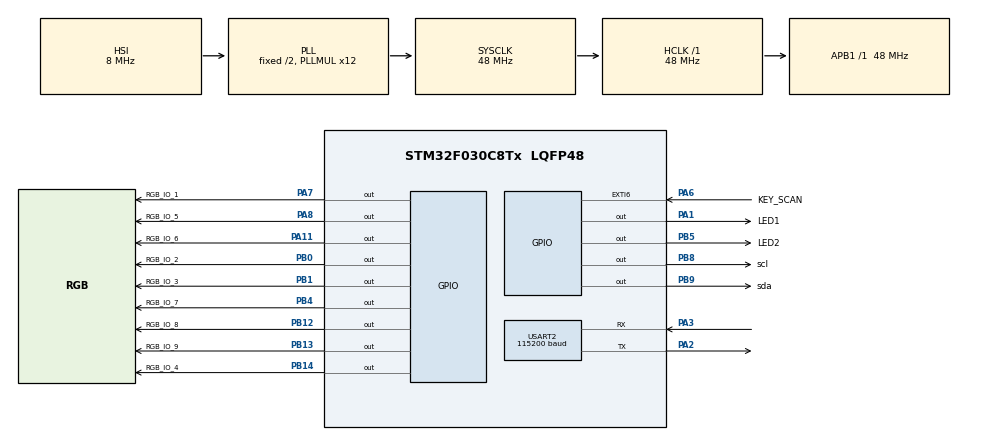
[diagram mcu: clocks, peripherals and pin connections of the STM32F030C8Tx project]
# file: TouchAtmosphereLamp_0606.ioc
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Dma.Request0=USART2_RX
Dma.Request1=USART2_TX
Dma.USART2_RX.0.Direction=DMA_PERIPH_TO_MEMORY
Dma.USART2_RX.0.Instance=DMA1_Channel5
Dma.USART2_RX.0.MemDataAlignment=DMA_MDATAALIGN_BYTE
Dma.USART2_RX.0.MemInc=DMA_MINC_ENABLE
Dma.USART2_RX.0.Mode=DMA_NORMAL
Dma.USART2_RX.0.PeriphDataAlignment=DMA_PDATAALIGN_BYTE
Dma.USART2_RX.0.PeriphInc=DMA_PINC_DISABLE
Dma.USART2_RX.0.Priority=DMA_PRIORITY_LOW
Dma.USART2_TX.1.Direction=DMA_MEMORY_TO_PERIPH
Dma.USART2_TX.1.Instance=DMA1_Channel4
Dma.USART2_TX.1.MemDataAlignment=DMA_MDATAALIGN_BYTE
Dma.USART2_TX.1.MemInc=DMA_MINC_ENABLE
Dma.USART2_TX.1.Mode=DMA_NORMAL
Dma.USART2_TX.1.PeriphDataAlignment=DMA_PDATAALIGN_BYTE
Dma.USART2_TX.1.PeriphInc=DMA_PINC_DISABLE
Dma.USART2_TX.1.Priority=DMA_PRIORITY_LOW
Mcu.Family=STM32F0
Mcu.Name=STM32F030C8Tx
Mcu.Package=LQFP48
NVIC.DMA1_Channel4_5_IRQn=true\:0\:0\:false\:false\:true\:false\:true\:true
NVIC.EXTI4_15_IRQn=true\:0\:0\:false\:false\:true\:true\:true\:true
NVIC.USART2_IRQn=true\:0\:0\:false\:false\:true\:true\:true\:true
PA1.GPIO_Label=LED1
PA1.Signal=GPIO_Output
PA11.GPIO_Label=RGB_IO_6
PA11.GPIO_PuPd=GPIO_PULLUP
PA11.Signal=GPIO_Output
PA13.Mode=Serial_Wire
PA13.Signal=SYS_SWDIO
PA14.Mode=Serial_Wire
PA14.Signal=SYS_SWCLK
PA2.GPIO_PuPd=GPIO_PULLUP
PA2.Mode=Asynchronous
PA2.Signal=USART2_TX
PA3.GPIO_PuPd=GPIO_PULLUP
PA3.Mode=Asynchronous
PA3.Signal=USART2_RX
PA6.GPIO_Label=KEY_SCAN
PA6.GPIO_ModeDefaultEXTI=GPIO_MODE_IT_FALLING
PA6.GPIO_PuPd=GPIO_PULLUP
PA6.Signal=GPXTI6
PA7.GPIO_Label=RGB_IO_1
PA7.GPIO_PuPd=GPIO_PULLUP
PA7.Signal=GPIO_Output
PA8.GPIO_Label=RGB_IO_5
PA8.GPIO_PuPd=GPIO_PULLUP
PA8.Signal=GPIO_Output
PB0.GPIO_Label=RGB_IO_2
PB0.GPIO_PuPd=GPIO_PULLUP
PB0.Signal=GPIO_Output
PB1.GPIO_Label=RGB_IO_3
PB1.GPIO_PuPd=GPIO_PULLUP
PB1.Signal=GPIO_Output
PB12.GPIO_Label=RGB_IO_8
PB12.GPIO_PuPd=GPIO_PULLUP
PB12.Signal=GPIO_Output
PB13.GPIO_Label=RGB_IO_9
PB13.GPIO_PuPd=GPIO_PULLUP
PB13.Signal=GPIO_Output
PB14.GPIO_Label=RGB_IO_4
PB14.GPIO_PuPd=GPIO_PULLUP
PB14.Signal=GPIO_Output
PB4.GPIO_Label=RGB_IO_7
PB4.GPIO_PuPd=GPIO_PULLUP
PB4.Signal=GPIO_Output
PB5.GPIO_Label=LED2
PB5.Signal=GPIO_Output
PB8.GPIO_Label=scl
PB8.Signal=GPIO_Output
PB9.GPIO_Label=sda
PB9.Signal=GPIO_Output
ProjectManager.HeapSize=0x200
ProjectManager.StackSize=0x400
ProjectManager.TargetToolchain=MDK-ARM V5.32
RCC.AHBFreq_Value=48000000
RCC.APB1Freq_Value=48000000
RCC.APB1TimFreq_Value=48000000
RCC.HCLKFreq_Value=48000000
RCC.PLLMUL=RCC_PLL_MUL12
RCC.SYSCLKFreq_VALUE=48000000
RCC.SYSCLKSource=RCC_SYSCLKSOURCE_PLLCLK
USART2.BaudRate=115200
USART2.VirtualMode-Asynchronous=VM_ASYNC
board=custom

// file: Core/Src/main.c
/* USER CODE BEGIN Header */
/**
  ******************************************************************************
  * @file           : main.c
  * @brief          : Main program body
  ******************************************************************************
  * @attention
  *
  * Copyright (c) 2022 STMicroelectronics.
  * All rights reserved.
  *
  * This software is licensed under terms that can be found in the LICENSE file
  * in the root directory of this software component.
  * If no LICENSE file comes with this software, it is provided AS-IS.
  *
  ******************************************************************************
  */
/* USER CODE END Header */
#include "main.h"

/* USER CODE BEGIN Includes */
#include "drv_serial.h"
#include "drv_rgb.h"
/* USER CODE END Includes */

 UART_HandleTypeDef huart2;
DMA_HandleTypeDef hdma_usart2_rx;
DMA_HandleTypeDef hdma_usart2_tx;

/* USER CODE BEGIN PV */
extern USART_RECEIVETYPE        UsartType2;

/* USER CODE END PV */

void SystemClock_Config(void);
static void MX_GPIO_Init(void);
static void MX_DMA_Init(void);
static void MX_USART2_UART_Init(void);

int main(void)
{

  /* MCU Configuration--------------------------------------------------------*/

  /* Reset of all peripherals, Initializes the Flash interface and the Systick. */
  HAL_Init();

  /* Configure the system clock */
  SystemClock_Config();

  /* USER CODE BEGIN SysInit */
  Drv_RGB_Init();
  /* USER CODE END SysInit */

  /* Initialize all configured peripherals */
  MX_GPIO_Init();
  MX_DMA_Init();
  MX_USART2_UART_Init();
  /* USER CODE BEGIN 2 */

  HAL_UART_Receive_DMA(&huart2, UsartType2.RX_pData, UART_RX_LEN);
  __HAL_UART_ENABLE_IT(&huart2, UART_IT_IDLE);

  Drv_SERIAL_Log("System running.");
  /* USER CODE END 2 */

  /* Infinite loop */
  /* USER CODE BEGIN WHILE */
  while (1)
  {
		Drv_LED_Proc();

    Drv_RGB_Proc();
    Drv_Panel_Proc();
    Drv_SERIAL_Proc();

    /* USER CODE END WHILE */

  }
}

void SystemClock_Config(void)
{
  RCC_OscInitTypeDef RCC_OscInitStruct = {0};
  RCC_ClkInitTypeDef RCC_ClkInitStruct = {0};

  /** Initializes the RCC Oscillators according to the specified parameters
  * in the RCC_OscInitTypeDef structure.
  */
  RCC_OscInitStruct.OscillatorType = RCC_OSCILLATORTYPE_HSI;
  RCC_OscInitStruct.HSIState = RCC_HSI_ON;
  RCC_OscInitStruct.HSICalibrationValue = RCC_HSICALIBRATION_DEFAULT;
  RCC_OscInitStruct.PLL.PLLState = RCC_PLL_ON;
  RCC_OscInitStruct.PLL.PLLSource = RCC_PLLSOURCE_HSI;
  RCC_OscInitStruct.PLL.PLLMUL = RCC_PLL_MUL12;
  RCC_OscInitStruct.PLL.PREDIV = RCC_PREDIV_DIV1;
  if (HAL_RCC_OscConfig(&RCC_OscInitStruct) != HAL_OK)
  {
    Error_Handler();
  }

  /** Initializes the CPU, AHB and APB buses clocks
  */
  RCC_ClkInitStruct.ClockType = RCC_CLOCKTYPE_HCLK|RCC_CLOCKTYPE_SYSCLK
                              |RCC_CLOCKTYPE_PCLK1;
  RCC_ClkInitStruct.SYSCLKSource = RCC_SYSCLKSOURCE_PLLCLK;
  RCC_ClkInitStruct.AHBCLKDivider = RCC_SYSCLK_DIV1;
  RCC_ClkInitStruct.APB1CLKDivider = RCC_HCLK_DIV1;

  if (HAL_RCC_ClockConfig(&RCC_ClkInitStruct, FLASH_LATENCY_1) != HAL_OK)
  {
    Error_Handler();
  }
}

static void MX_USART2_UART_Init(void)
{

  huart2.Instance = USART2;
  huart2.Init.BaudRate = 115200;
  huart2.Init.WordLength = UART_WORDLENGTH_8B;
  huart2.Init.StopBits = UART_STOPBITS_1;
  huart2.Init.Parity = UART_PARITY_NONE;
  huart2.Init.Mode = UART_MODE_TX_RX;
  huart2.Init.HwFlowCtl = UART_HWCONTROL_NONE;
  huart2.Init.OverSampling = UART_OVERSAMPLING_16;
  huart2.Init.OneBitSampling = UART_ONE_BIT_SAMPLE_DISABLE;
  huart2.AdvancedInit.AdvFeatureInit = UART_ADVFEATURE_NO_INIT;
  if (HAL_UART_Init(&huart2) != HAL_OK)
  {
    Error_Handler();
  }

}

static void MX_DMA_Init(void)
{

  /* DMA controller clock enable */
  __HAL_RCC_DMA1_CLK_ENABLE();

  /* DMA interrupt init */
  /* DMA1_Channel4_5_IRQn interrupt configuration */
  HAL_NVIC_SetPriority(DMA1_Channel4_5_IRQn, 0, 0);
  HAL_NVIC_EnableIRQ(DMA1_Channel4_5_IRQn);

}

static void MX_GPIO_Init(void)
{
  GPIO_InitTypeDef GPIO_InitStruct = {0};

  /* GPIO Ports Clock Enable */
  __HAL_RCC_GPIOA_CLK_ENABLE();
  __HAL_RCC_GPIOB_CLK_ENABLE();

  /*Configure GPIO pin Output Level */
  HAL_GPIO_WritePin(GPIOA, LED1_Pin|RGB_IO_4_Pin|RGB_IO_8_Pin|RGB_IO_9_Pin, GPIO_PIN_RESET);

  /*Configure GPIO pin Output Level */
  HAL_GPIO_WritePin(GPIOB, RGB_IO_1_Pin|RGB_IO_2_Pin|RGB_IO_3_Pin|RGB_IO_5_Pin
                          |RGB_IO_6_Pin|RGB_IO_7_Pin|LED2_Pin|scl_Pin
                          |sda_Pin, GPIO_PIN_RESET);

  /*Configure GPIO pin : LED1_Pin */
  GPIO_InitStruct.Pin = LED1_Pin;
  GPIO_InitStruct.Mode = GPIO_MODE_OUTPUT_PP;
  GPIO_InitStruct.Pull = GPIO_NOPULL;
  GPIO_InitStruct.Speed = GPIO_SPEED_FREQ_LOW;
  HAL_GPIO_Init(LED1_GPIO_Port, &GPIO_InitStruct);

  /*Configure GPIO pin : KEY_SCAN_Pin */
  GPIO_InitStruct.Pin = KEY_SCAN_Pin;
  GPIO_InitStruct.Mode = GPIO_MODE_IT_FALLING;
  GPIO_InitStruct.Pull = GPIO_PULLUP;
  HAL_GPIO_Init(KEY_SCAN_GPIO_Port, &GPIO_InitStruct);

  GPIO_InitStruct.Pin = RGB_IO_4_Pin|RGB_IO_8_Pin|RGB_IO_9_Pin;
  GPIO_InitStruct.Mode = GPIO_MODE_OUTPUT_PP;
  GPIO_InitStruct.Pull = GPIO_PULLUP;
  GPIO_InitStruct.Speed = GPIO_SPEED_FREQ_LOW;
  HAL_GPIO_Init(GPIOA, &GPIO_InitStruct);

  GPIO_InitStruct.Pin = RGB_IO_1_Pin|RGB_IO_2_Pin|RGB_IO_3_Pin|RGB_IO_5_Pin
                          |RGB_IO_6_Pin|RGB_IO_7_Pin;
  GPIO_InitStruct.Mode = GPIO_MODE_OUTPUT_PP;
  GPIO_InitStruct.Pull = GPIO_PULLUP;
  GPIO_InitStruct.Speed = GPIO_SPEED_FREQ_LOW;
  HAL_GPIO_Init(GPIOB, &GPIO_InitStruct);

  /*Configure GPIO pins : LED2_Pin scl_Pin sda_Pin */
  GPIO_InitStruct.Pin = LED2_Pin|scl_Pin|sda_Pin;
  GPIO_InitStruct.Mode = GPIO_MODE_OUTPUT_PP;
  GPIO_InitStruct.Pull = GPIO_NOPULL;
  GPIO_InitStruct.Speed = GPIO_SPEED_FREQ_LOW;
  HAL_GPIO_Init(GPIOB, &GPIO_InitStruct);

  /* EXTI interrupt init*/
  HAL_NVIC_SetPriority(EXTI4_15_IRQn, 0, 0);
  HAL_NVIC_EnableIRQ(EXTI4_15_IRQn);

}

void Error_Handler(void)
{
  __disable_irq();
  while (1)
  {
  }
}
